AUTOSAR XML (schema 00046)
package /ComponentTypes
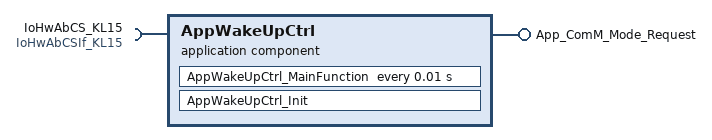
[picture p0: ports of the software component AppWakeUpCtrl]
  application sw component type AppWakeUpCtrl
    provide port App_ComM_Mode_Request: nonqueued-sender-com-spec=Request_Mode, provided-interface=App_ComM_Mode_Request
    require port IoHwAbCS_KL15: required-com-specs=[IoHwAbOp_KL15_Read], required-interface=IoHwAbCSIf_KL15
    behavior AppWakeUpCtrl_InternalBehavior
      timing event TMT_AppWakeUpCtrl_MainFunction: start-on-event=AppWakeUpCtrl_MainFunction, period=0.01
      init event AppWakeUpCtrl_InitEvent: start-on-event=AppWakeUpCtrl_Init
      runnable AppWakeUpCtrl_MainFunction
        data-send-points:
          access SEND_App_ComM_Mode_Request_Request_Mode: accessed-variable=App_ComM_Mode_Request.Request_Mode
        sync call SC_IoHwAbCS_KL15_IoHwAbOp_KL15_Read: operation=IoHwAbCS_KL15.IoHwAbOp_KL15_Read
        sync call SC_IoHwAbCS_KL15_IoHwAbOp_KL15_Write: operation=IoHwAbCS_KL15
      runnable AppWakeUpCtrl_Init
  swc implementation AppWakeUpCtrl_Implementation: behavior=AppWakeUpCtrl_InternalBehavior
